AUTOSAR XML (schema 3.1.2)
package /Components/SWC_OilSys
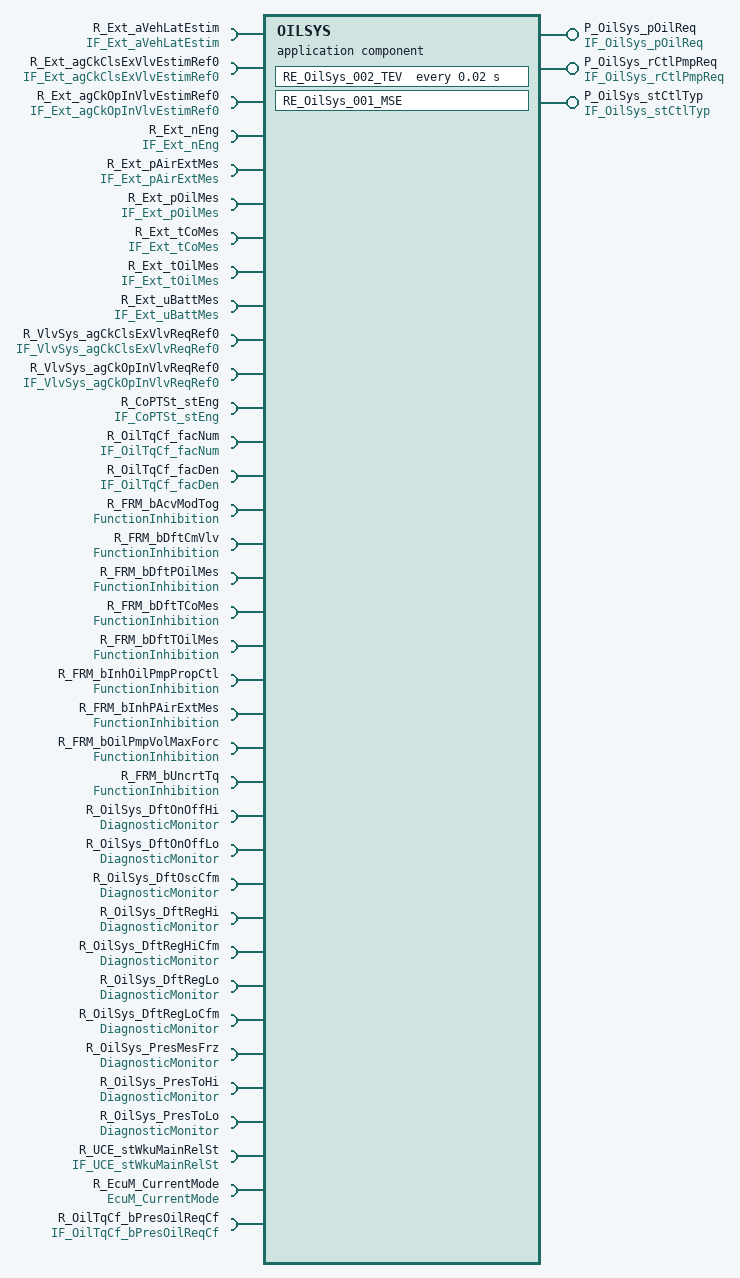
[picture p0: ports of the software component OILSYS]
  application software component type OILSYS
    23 x require port:
      R_Ext_aVehLatEstim: unqueued-receiver-com-spec{data-element=Ext_aVehLatEstim, init-value=Ext_aVehLatEstim_in, resync-time=0}, required-interface=IF_Ext_aVehLatEstim
      R_Ext_agCkClsExVlvEstimRef0: unqueued-receiver-com-spec{data-element=Ext_agCkClsExVlvEstimRef0, init-value=Ext_agCkClsExVlvEstimRef0_in, resync-time=0}, required-interface=IF_Ext_agCkClsExVlvEstimRef0
      R_Ext_agCkOpInVlvEstimRef0: unqueued-receiver-com-spec{data-element=Ext_agCkOpInVlvEstimRef0, init-value=Ext_agCkOpInVlvEstimRef0_in, resync-time=0}, required-interface=IF_Ext_agCkOpInVlvEstimRef0
      R_Ext_nEng: unqueued-receiver-com-spec{data-element=Ext_nEng, init-value=ConstantValue, resync-time=0}, required-interface=IF_Ext_nEng
      R_Ext_pAirExtMes: unqueued-receiver-com-spec{data-element=Ext_pAirExtMes, init-value=Ext_pAirExtMes_in, resync-time=0}, required-interface=IF_Ext_pAirExtMes
      R_Ext_pOilMes: unqueued-receiver-com-spec{data-element=Ext_pOilMes, init-value=Ext_pOilMes_in, resync-time=0}, required-interface=IF_Ext_pOilMes
      R_Ext_tCoMes: unqueued-receiver-com-spec{data-element=Ext_tCoMes, init-value=ConstantValue1, resync-time=0}, required-interface=IF_Ext_tCoMes
      R_Ext_tOilMes: unqueued-receiver-com-spec{data-element=Ext_tOilMes, init-value=Ext_tOilMes_in, resync-time=0}, required-interface=IF_Ext_tOilMes
      R_Ext_uBattMes: unqueued-receiver-com-spec{data-element=Ext_uBattMes, init-value=Ext_uBattMes_in, resync-time=0}, required-interface=IF_Ext_uBattMes
      R_VlvSys_agCkClsExVlvReqRef0: unqueued-receiver-com-spec{data-element=VlvSys_agCkClsExVlvReqRef0, init-value=VlvSys_agCkClsExVlvReqRef0_in, resync-time=0}, required-interface=IF_VlvSys_agCkClsExVlvReqRef0
      R_VlvSys_agCkOpInVlvReqRef0: unqueued-receiver-com-spec{data-element=VlvSys_agCkOpInVlvReqRef0, init-value=VlvSys_agCkOpInVlvReqRef0_in, resync-time=0}, required-interface=IF_VlvSys_agCkOpInVlvReqRef0
      R_CoPTSt_stEng: unqueued-receiver-com-spec{data-element=CoPTSt_stEng, init-value=CoPTSt_stEng_in, resync-time=0}, required-interface=IF_CoPTSt_stEng
      R_OilTqCf_facNum: unqueued-receiver-com-spec{data-element=OilTqCf_facNum, init-value=OilTqCf_facNum, resync-time=0}, required-interface=IF_OilTqCf_facNum
      R_OilTqCf_facDen: unqueued-receiver-com-spec{data-element=OilTqCf_facDen, init-value=OilTqCf_facDen_Cst, resync-time=0}, required-interface=IF_OilTqCf_facDen
      R_FRM_bAcvModTog: required-interface=FunctionInhibition
      R_FRM_bDftCmVlv: required-interface=FunctionInhibition
      R_FRM_bDftPOilMes: required-interface=FunctionInhibition
      R_FRM_bDftTCoMes: required-interface=FunctionInhibition
      R_FRM_bDftTOilMes: required-interface=FunctionInhibition
      R_FRM_bInhOilPmpPropCtl: required-interface=FunctionInhibition
      R_FRM_bInhPAirExtMes: required-interface=FunctionInhibition
      R_FRM_bOilPmpVolMaxForc: required-interface=FunctionInhibition
      R_FRM_bUncrtTq: required-interface=FunctionInhibition
    provide port P_OilSys_pOilReq: unqueued-sender-com-spec{data-element=OilSys_pOilReq, can-invalidate=false, init-value=OilSys_pOilReq_out}, provided-interface=IF_OilSys_pOilReq
    provide port P_OilSys_rCtlPmpReq: unqueued-sender-com-spec{data-element=OilSys_rCtlPmpReq, can-invalidate=false, init-value=OilSys_rCtlPmpReq_out}, provided-interface=IF_OilSys_rCtlPmpReq
    13 x require port:
      R_OilSys_DftOnOffHi: required-interface=DiagnosticMonitor
      R_OilSys_DftOnOffLo: required-interface=DiagnosticMonitor
      R_OilSys_DftOscCfm: required-interface=DiagnosticMonitor
      R_OilSys_DftRegHi: required-interface=DiagnosticMonitor
      R_OilSys_DftRegHiCfm: required-interface=DiagnosticMonitor
      R_OilSys_DftRegLo: required-interface=DiagnosticMonitor
      R_OilSys_DftRegLoCfm: required-interface=DiagnosticMonitor
      R_OilSys_PresMesFrz: required-interface=DiagnosticMonitor
      R_OilSys_PresToHi: required-interface=DiagnosticMonitor
      R_OilSys_PresToLo: required-interface=DiagnosticMonitor
      R_UCE_stWkuMainRelSt: required-interface=IF_UCE_stWkuMainRelSt
      R_EcuM_CurrentMode: required-interface=EcuM_CurrentMode
      R_OilTqCf_bPresOilReqCf: unqueued-receiver-com-spec{data-element=OilTqCf_bPresOilReqCf, init-value=OilTqCf_bPresOilReqCf_Cst, resync-time=0}, required-interface=IF_OilTqCf_bPresOilReqCf
    provide port P_OilSys_stCtlTyp: unqueued-sender-com-spec{data-element=OilSys_stCtlTyp, can-invalidate=false, init-value=OilSys_stCtlTyp_Cst}, provided-interface=IF_OilSys_stCtlTyp
  18 x constant specification:
    ConstantValue
      value:
        integer literal ConstantValue: type=DT_Ext_nEng, value=0
    ConstantValue1
      value:
        integer literal ConstantValue1: type=DT_Ext_tCoMes, value=20
    CoPTSt_stEng_in
      value:
        integer literal CoPTSt_stEng_in: type=DT_CoPTSt_stEng, value=1
    Ext_agCkClsExVlvEstimRef0_in
      value:
        integer literal Ext_agCkClsExVlvEstimRef0_in: type=DT_Ext_agCkClsExVlvEstimRef0, value=-1024
    Ext_agCkOpInVlvEstimRef0_in
      value:
        integer literal Ext_agCkOpInVlvEstimRef0_in: type=DT_Ext_agCkOpInVlvEstimRef0, value=-1024
    Ext_aVehLatEstim_in
      value:
        integer literal Ext_aVehLatEstim_in: type=DT_Ext_aVehLatEstim, value=0
    Ext_pAirExtMes_in
      value:
        integer literal Ext_pAirExtMes_in: type=DT_Ext_pAirExtMes, value=500
    Ext_pOilMes_in
      value:
        integer literal Ext_pOilMes_in: type=DT_Ext_pOilMes, value=0
    Ext_tOilMes_in
      value:
        integer literal Ext_tOilMes_in: type=DT_Ext_tOilMes, value=0
    Ext_uBattMes_in
      value:
        integer literal Ext_uBattMes_in: type=DT_Ext_uBattMes, value=1200
    OilSys_pOilReq_out
      value:
        integer literal OilSys_pOilReq_out: type=DT_OilSys_pOilReq, value=0
    OilSys_rCtlPmpReq_out
      value:
        integer literal OilSys_rCtlPmpReq_out: type=DT_OilSys_rCtlPmpReq, value=0
    OilSys_stCtlTyp_Cst
      value:
        integer literal OilSys_stCtlTyp_Cst: type=DT_OilSys_stCtlTyp, value=0
    OilTqCf_bPresOilReqCf_Cst
      value:
        boolean literal OilTqCf_bPresOilReqCf_Cst: type=DT_OilTqCf_bPresOilReqCf, value=false
    OilTqCf_facDen_Cst
      value:
        integer literal OilTqCf_facDen_Cst: type=DT_OilTqCf_facDen, value=0
    OilTqCf_facNum
      value:
        integer literal OilTqCf_facNum: type=DT_OilTqCf_facNum, value=0
    VlvSys_agCkClsExVlvReqRef0_in
      value:
        integer literal VlvSys_agCkClsExVlvReqRef0_in: type=DT_VlvSys_agCkClsExVlvReqRef0, value=128
    VlvSys_agCkOpInVlvReqRef0_in
      value:
        integer literal VlvSys_agCkOpInVlvReqRef0_in: type=DT_VlvSys_agCkOpInVlvReqRef0, value=128
  internal behavior IB_OilSys: component=OILSYS
    mode switch event EV_OilSys_001_MSE: start-on-event=RE_OilSys_001_MSE, activation=ENTRY, mode=R_EcuM_CurrentMode.currentMode.RUN
    timing event EV_OilSys_002_TEV: start-on-event=RE_OilSys_002_TEV, period=0.02
    runnable RE_OilSys_002_TEV
      15 x data receive point:
        dr_Ext_agCkClsExVlvEstimRef0: data-element=R_Ext_agCkClsExVlvEstimRef0.Ext_agCkClsExVlvEstimRef0
        dr_Ext_tCoMes: data-element=R_Ext_tCoMes.Ext_tCoMes
        dr_VlvSys_agCkOpInVlvReqRef0: data-element=R_VlvSys_agCkOpInVlvReqRef0.VlvSys_agCkOpInVlvReqRef0
        dr_Ext_tOilMes: data-element=R_Ext_tOilMes.Ext_tOilMes
        dr_Ext_pAirExtMes: data-element=R_Ext_pAirExtMes.Ext_pAirExtMes
        dr_CoPTSt_stEng: data-element=R_CoPTSt_stEng.CoPTSt_stEng
        dr_VlvSys_agCkClsExVlvReqRef0: data-element=R_VlvSys_agCkClsExVlvReqRef0.VlvSys_agCkClsExVlvReqRef0
        dr_Ext_nEng: data-element=R_Ext_nEng.Ext_nEng
        dr_Ext_uBattMes: data-element=R_Ext_uBattMes.Ext_uBattMes
        dr_Ext_agCkOpInVlvEstimRef0: data-element=R_Ext_agCkOpInVlvEstimRef0.Ext_agCkOpInVlvEstimRef0
        dr_Ext_pOilMes: data-element=R_Ext_pOilMes.Ext_pOilMes
        dr_Ext_aVehLatEstim: data-element=R_Ext_aVehLatEstim.Ext_aVehLatEstim
        dr_OilTqCf_bPresOilReqCf: data-element=R_OilTqCf_bPresOilReqCf.OilTqCf_bPresOilReqCf
        dr_OilTqCf_facDen: data-element=R_OilTqCf_facDen.OilTqCf_facDen
        dr_OilTqCf_facNum: data-element=R_OilTqCf_facNum.OilTqCf_facNum
      data send point ds_OilSys_rCtlPmpReq: data-element=P_OilSys_rCtlPmpReq.OilSys_rCtlPmpReq
      data send point ds_OilSys_pOilReq: data-element=P_OilSys_pOilReq.OilSys_pOilReq
      data send point ds_OilSys_stCtlTyp: data-element=P_OilSys_stCtlTyp.OilSys_stCtlTyp
      19 x sync call:
        ssp_OilSys_PresToLo: operation=R_OilSys_PresToLo.SetEventStatus
        ssp_OilSys_PresMesFrz: operation=R_OilSys_PresMesFrz.SetEventStatus
        ssp_FRM_bDftTOilMes: operation=R_FRM_bDftTOilMes.GetFunctionPermission
        ssp_FRM_bInhPAirExtMes: operation=R_FRM_bInhPAirExtMes.GetFunctionPermission
        ssp_FRM_bAcvModTog: operation=R_FRM_bAcvModTog.GetFunctionPermission
        ssp_FRM_bInhOilPmpPropCtl: operation=R_FRM_bInhOilPmpPropCtl.GetFunctionPermission
        ssp_OilSys_DftOscCfm: operation=R_OilSys_DftOscCfm.SetEventStatus
        ssp_OilSys_DftRegLo: operation=R_OilSys_DftRegLo.SetEventStatus
        ssp_FRM_bDftPOilMes: operation=R_FRM_bDftPOilMes.GetFunctionPermission
        ssp_OilSys_DftRegHiCfm: operation=R_OilSys_DftRegHiCfm.SetEventStatus
        ssp_FRM_bDftTCoMes: operation=R_FRM_bDftTCoMes.GetFunctionPermission
        ssp_OilSys_PresToHi: operation=R_OilSys_PresToHi.SetEventStatus
        ssp_OilSys_DftOnOffLo: operation=R_OilSys_DftOnOffLo.SetEventStatus
        ssp_FRM_bDftCmVlv: operation=R_FRM_bDftCmVlv.GetFunctionPermission
        ssp_FRM_bOilPmpVolMaxForc: operation=R_FRM_bOilPmpVolMaxForc.GetFunctionPermission
        ssp_OilSys_DftOnOffHi: operation=R_OilSys_DftOnOffHi.SetEventStatus
        ssp_FRM_bUncrtTq: operation=R_FRM_bUncrtTq.GetFunctionPermission
        ssp_OilSys_DftRegHi: operation=R_OilSys_DftRegHi.SetEventStatus
        ssp_OilSys_DftRegLoCfm: operation=R_OilSys_DftRegLoCfm.SetEventStatus
    runnable RE_OilSys_001_MSE
      data send point ds_OilSys_stCtlTyp: data-element=P_OilSys_stCtlTyp.OilSys_stCtlTyp
      data send point ds_OilSys_rCtlPmpReq: data-element=P_OilSys_rCtlPmpReq.OilSys_rCtlPmpReq
      data send point ds_OilSys_pOilReq: data-element=P_OilSys_pOilReq.OilSys_pOilReq
  swc implementation Imp_OilSys: programming-language=C, behavior=IB_OilSys
    code-descriptors:
      code CodeDescriptor: type=SRC
        7 x xfile:
          OilSys_002_TEV_fct_h: url=OilSys_002_TEV_fct.h
          OilSys_calibrations_c: url=OilSys_calibrations.c
          OilSys_MemMap_h: url=OilSys_MemMap.h
          OilSys_c: url=OilSys.c
          OilSys_calibrations_h: url=OilSys_calibrations.h
          OilSys_h: url=OilSys.h
          OilSys_002_TEV_fct_c: url=OilSys_002_TEV_fct.c
